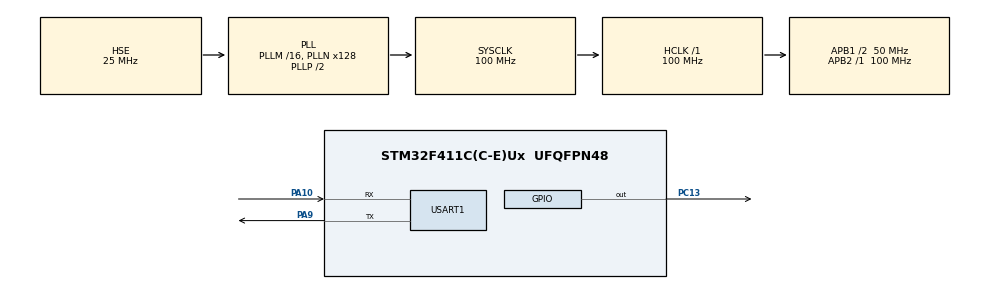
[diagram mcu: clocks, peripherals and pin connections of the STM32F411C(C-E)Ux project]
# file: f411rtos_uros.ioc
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Dma.Request0=USART1_RX
Dma.Request1=USART1_TX
Dma.USART1_RX.0.Direction=DMA_PERIPH_TO_MEMORY
Dma.USART1_RX.0.FIFOMode=DMA_FIFOMODE_DISABLE
Dma.USART1_RX.0.Instance=DMA2_Stream2
Dma.USART1_RX.0.MemDataAlignment=DMA_MDATAALIGN_BYTE
Dma.USART1_RX.0.MemInc=DMA_MINC_ENABLE
Dma.USART1_RX.0.Mode=DMA_CIRCULAR
Dma.USART1_RX.0.PeriphDataAlignment=DMA_PDATAALIGN_BYTE
Dma.USART1_RX.0.PeriphInc=DMA_PINC_DISABLE
Dma.USART1_RX.0.Priority=DMA_PRIORITY_HIGH
Dma.USART1_TX.1.Direction=DMA_MEMORY_TO_PERIPH
Dma.USART1_TX.1.FIFOMode=DMA_FIFOMODE_DISABLE
Dma.USART1_TX.1.Instance=DMA2_Stream7
Dma.USART1_TX.1.MemDataAlignment=DMA_MDATAALIGN_BYTE
Dma.USART1_TX.1.MemInc=DMA_MINC_ENABLE
Dma.USART1_TX.1.Mode=DMA_NORMAL
Dma.USART1_TX.1.PeriphDataAlignment=DMA_PDATAALIGN_BYTE
Dma.USART1_TX.1.PeriphInc=DMA_PINC_DISABLE
Dma.USART1_TX.1.Priority=DMA_PRIORITY_HIGH
FREERTOS.Tasks01=defaultTask,24,128,StartDefaultTask,Default,NULL,Dynamic,NULL,NULL;rosTask,40,3000,StartRosTask,Default,NULL,Dynamic,NULL,NULL
FREERTOS.configENABLE_FPU=1
FREERTOS.configUSE_NEWLIB_REENTRANT=1
Mcu.Family=STM32F4
Mcu.Name=STM32F411C(C-E)Ux
Mcu.Package=UFQFPN48
NVIC.DMA2_Stream2_IRQn=true\:5\:0\:false\:false\:true\:true\:false\:true\:true
NVIC.DMA2_Stream7_IRQn=true\:5\:0\:false\:false\:true\:true\:false\:true\:true
NVIC.PriorityGroup=NVIC_PRIORITYGROUP_4
NVIC.TIM1_UP_TIM10_IRQn=true\:15\:0\:false\:false\:true\:false\:false\:true\:true
NVIC.TimeBase=TIM1_UP_TIM10_IRQn
NVIC.TimeBaseIP=TIM1
NVIC.USART1_IRQn=true\:5\:0\:false\:false\:true\:true\:true\:true\:true
PA10.Mode=Asynchronous
PA10.Signal=USART1_RX
PA13.Mode=Serial_Wire
PA13.Signal=SYS_JTMS-SWDIO
PA14.Mode=Serial_Wire
PA14.Signal=SYS_JTCK-SWCLK
PA9.Mode=Asynchronous
PA9.Signal=USART1_TX
PC13-ANTI_TAMP.Signal=GPIO_Output
PH0\ -\ OSC_IN.Mode=HSE-External-Oscillator
PH0\ -\ OSC_IN.Signal=RCC_OSC_IN
PH1\ -\ OSC_OUT.Mode=HSE-External-Oscillator
PH1\ -\ OSC_OUT.Signal=RCC_OSC_OUT
ProjectManager.HeapSize=0x200
ProjectManager.StackSize=0x400
ProjectManager.TargetToolchain=STM32CubeIDE
RCC.48MHZClocksFreq_Value=50000000
RCC.AHBFreq_Value=100000000
RCC.APB1CLKDivider=RCC_HCLK_DIV2
RCC.APB1Freq_Value=50000000
RCC.APB1TimFreq_Value=100000000
RCC.APB2Freq_Value=100000000
RCC.APB2TimFreq_Value=100000000
RCC.CortexFreq_Value=100000000
RCC.HCLKFreq_Value=100000000
RCC.HSE_VALUE=25000000
RCC.HSI_VALUE=16000000
RCC.LSE_VALUE=32768
RCC.PLLN=128
RCC.PLLSourceVirtual=RCC_PLLSOURCE_HSE
RCC.SYSCLKFreq_VALUE=100000000
RCC.SYSCLKSource=RCC_SYSCLKSOURCE_PLLCLK
RCC.VCOOutputFreq_Value=200000000
USART1.VirtualMode=VM_ASYNC
VP_FREERTOS_VS_CMSIS_V2.Mode=CMSIS_V2
VP_SYS_VS_tim1.Mode=TIM1
board=custom

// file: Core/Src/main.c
/* USER CODE BEGIN Header */
/**
  ******************************************************************************
  * @file           : main.c
  * @brief          : Main program body
  ******************************************************************************
  * @attention
  *
  * Copyright (c) 2025 STMicroelectronics.
  * All rights reserved.
  *
  * This software is licensed under terms that can be found in the LICENSE file
  * in the root directory of this software component.
  * If no LICENSE file comes with this software, it is provided AS-IS.
  *
  ******************************************************************************
  */
/* USER CODE END Header */
#include "main.h"
#include "cmsis_os.h"

/* USER CODE BEGIN Includes */

// micro-ros includes
#include <rcl/rcl.h>
#include <rcl/error_handling.h>
#include <rclc/rclc.h>
#include <rclc/executor.h>
#include <uxr/client/transport.h>
#include <rmw_microxrcedds_c/config.h>
#include <rmw_microros/rmw_microros.h>

#include <std_msgs/msg/int32.h>
#include <geometry_msgs/msg/twist.h>

/* USER CODE END Includes */

UART_HandleTypeDef huart1;
DMA_HandleTypeDef hdma_usart1_rx;
DMA_HandleTypeDef hdma_usart1_tx;

/* Definitions for defaultTask */
osThreadId_t defaultTaskHandle;
const osThreadAttr_t defaultTask_attributes = {
  .name = "defaultTask",
  .stack_size = 128 * 4,
  .priority = (osPriority_t) osPriorityNormal,
};
/* Definitions for rosTask */
osThreadId_t rosTaskHandle;
const osThreadAttr_t rosTask_attributes = {
  .name = "rosTask",
  .stack_size = 3000 * 4,
  .priority = (osPriority_t) osPriorityHigh,
};
/* USER CODE BEGIN PV */

// micro-ros node
rcl_node_t node;

// micro-ros publisher
rcl_publisher_t publisher;

// micro-ros subscriber
rcl_subscription_t cmd_vel_sub;
rclc_executor_t executor;
geometry_msgs__msg__Twist cmd_vel_msg;

volatile float v_linear = 0.0f;
volatile float v_angular = 0.0f;

//volatile uint32_t cb_count = 0;

/* USER CODE END PV */

void SystemClock_Config(void);
static void MX_GPIO_Init(void);
static void MX_DMA_Init(void);
static void MX_USART1_UART_Init(void);
void StartDefaultTask(void *argument);
void StartRosTask(void *argument);

/* USER CODE BEGIN PFP */

// micro-ros
bool cubemx_transport_open(struct uxrCustomTransport * transport);
bool cubemx_transport_close(struct uxrCustomTransport * transport);
size_t cubemx_transport_write(struct uxrCustomTransport* transport, const uint8_t * buf, size_t len, uint8_t * err);
size_t cubemx_transport_read(struct uxrCustomTransport* transport, uint8_t* buf, size_t len, int timeout, uint8_t* err);

void * microros_allocate(size_t size, void * state);
void microros_deallocate(void * pointer, void * state);
void * microros_reallocate(void * pointer, size_t size, void * state);
void * microros_zero_allocate(size_t number_of_elements, size_t size_of_element, void * state);

// micro-ros subscriber
void cmd_vel_callback(const void * msgin);

/* USER CODE END PFP */

/* USER CODE BEGIN 0 */

__attribute__((noinline)) void cmd_vel_callback(const void * msgin)
{
  const geometry_msgs__msg__Twist * msg = (const geometry_msgs__msg__Twist *)msgin;

  HAL_GPIO_TogglePin(GPIOC, GPIO_PIN_13);

  //cb_count++;

  v_linear  = msg->linear.x;
  v_angular = msg->angular.z;
}

/* USER CODE END 0 */

int main(void)
{

  /* MCU Configuration--------------------------------------------------------*/

  /* Reset of all peripherals, Initializes the Flash interface and the Systick. */
  HAL_Init();

  /* Configure the system clock */
  SystemClock_Config();

  /* Initialize all configured peripherals */
  MX_GPIO_Init();
  MX_DMA_Init();
  MX_USART1_UART_Init();

  /* Init scheduler */
  osKernelInitialize();

  /* Create the thread(s) */
  /* creation of defaultTask */
  defaultTaskHandle = osThreadNew(StartDefaultTask, NULL, &defaultTask_attributes);

  /* creation of rosTask */
  rosTaskHandle = osThreadNew(StartRosTask, NULL, &rosTask_attributes);

  /* Start scheduler */
  osKernelStart();

  /* We should never get here as control is now taken by the scheduler */

  /* Infinite loop */
  while (1)
  {

  }
}

void SystemClock_Config(void)
{
  RCC_OscInitTypeDef RCC_OscInitStruct = {0};
  RCC_ClkInitTypeDef RCC_ClkInitStruct = {0};

  /** Configure the main internal regulator output voltage
  */
  __HAL_RCC_PWR_CLK_ENABLE();
  __HAL_PWR_VOLTAGESCALING_CONFIG(PWR_REGULATOR_VOLTAGE_SCALE1);

  /** Initializes the RCC Oscillators according to the specified parameters
  * in the RCC_OscInitTypeDef structure.
  */
  RCC_OscInitStruct.OscillatorType = RCC_OSCILLATORTYPE_HSE;
  RCC_OscInitStruct.HSEState = RCC_HSE_ON;
  RCC_OscInitStruct.PLL.PLLState = RCC_PLL_ON;
  RCC_OscInitStruct.PLL.PLLSource = RCC_PLLSOURCE_HSE;
  RCC_OscInitStruct.PLL.PLLM = 16;
  RCC_OscInitStruct.PLL.PLLN = 128;
  RCC_OscInitStruct.PLL.PLLP = RCC_PLLP_DIV2;
  RCC_OscInitStruct.PLL.PLLQ = 4;
  if (HAL_RCC_OscConfig(&RCC_OscInitStruct) != HAL_OK)
  {
    Error_Handler();
  }

  /** Initializes the CPU, AHB and APB buses clocks
  */
  RCC_ClkInitStruct.ClockType = RCC_CLOCKTYPE_HCLK|RCC_CLOCKTYPE_SYSCLK
                              |RCC_CLOCKTYPE_PCLK1|RCC_CLOCKTYPE_PCLK2;
  RCC_ClkInitStruct.SYSCLKSource = RCC_SYSCLKSOURCE_PLLCLK;
  RCC_ClkInitStruct.AHBCLKDivider = RCC_SYSCLK_DIV1;
  RCC_ClkInitStruct.APB1CLKDivider = RCC_HCLK_DIV2;
  RCC_ClkInitStruct.APB2CLKDivider = RCC_HCLK_DIV1;

  if (HAL_RCC_ClockConfig(&RCC_ClkInitStruct, FLASH_LATENCY_3) != HAL_OK)
  {
    Error_Handler();
  }
}

static void MX_USART1_UART_Init(void)
{

  huart1.Instance = USART1;
  huart1.Init.BaudRate = 115200;
  huart1.Init.WordLength = UART_WORDLENGTH_8B;
  huart1.Init.StopBits = UART_STOPBITS_1;
  huart1.Init.Parity = UART_PARITY_NONE;
  huart1.Init.Mode = UART_MODE_TX_RX;
  huart1.Init.HwFlowCtl = UART_HWCONTROL_NONE;
  huart1.Init.OverSampling = UART_OVERSAMPLING_16;
  if (HAL_UART_Init(&huart1) != HAL_OK)
  {
    Error_Handler();
  }

}

static void MX_DMA_Init(void)
{

  /* DMA controller clock enable */
  __HAL_RCC_DMA2_CLK_ENABLE();

  /* DMA interrupt init */
  /* DMA2_Stream2_IRQn interrupt configuration */
  HAL_NVIC_SetPriority(DMA2_Stream2_IRQn, 5, 0);
  HAL_NVIC_EnableIRQ(DMA2_Stream2_IRQn);
  /* DMA2_Stream7_IRQn interrupt configuration */
  HAL_NVIC_SetPriority(DMA2_Stream7_IRQn, 5, 0);
  HAL_NVIC_EnableIRQ(DMA2_Stream7_IRQn);

}

static void MX_GPIO_Init(void)
{
  GPIO_InitTypeDef GPIO_InitStruct = {0};

  /* GPIO Ports Clock Enable */
  __HAL_RCC_GPIOC_CLK_ENABLE();
  __HAL_RCC_GPIOH_CLK_ENABLE();
  __HAL_RCC_GPIOA_CLK_ENABLE();

  /*Configure GPIO pin Output Level */
  HAL_GPIO_WritePin(GPIOC, GPIO_PIN_13, GPIO_PIN_RESET);

  /*Configure GPIO pin : PC13 */
  GPIO_InitStruct.Pin = GPIO_PIN_13;
  GPIO_InitStruct.Mode = GPIO_MODE_OUTPUT_PP;
  GPIO_InitStruct.Pull = GPIO_NOPULL;
  GPIO_InitStruct.Speed = GPIO_SPEED_FREQ_LOW;
  HAL_GPIO_Init(GPIOC, &GPIO_InitStruct);

}

void StartDefaultTask(void *argument)
{
  /* USER CODE BEGIN 5 */
  /* Infinite loop */
  for(;;)
  {
	// my led blink
	//HAL_GPIO_TogglePin(GPIOC, GPIO_PIN_13);
	osDelay(1000);
  }
  /* USER CODE END 5 */
}

void StartRosTask(void *argument)
{
  /* USER CODE BEGIN StartRosTask */
	  std_msgs__msg__Int32 msg;
	  rclc_support_t support;
	  rcl_allocator_t allocator;

	  /*
	  static bool initialized = false;
	  if (initialized) vTaskDelete(NULL);
	  initialized = true;
	  */
	  osDelay(1000);

	  rmw_uros_set_custom_transport(
	    true,
	    (void *) &huart1,
	    cubemx_transport_open,
	    cubemx_transport_close,
	    cubemx_transport_write,
	    cubemx_transport_read);

	  /*
	  while (rmw_uros_ping_agent(1000, 1) != RMW_RET_OK)
	  {
	    osDelay(1000);
	  }
	  */

	  //rmw_uros_sync_session(1000);

	  /*
	  rcl_allocator_t freeRTOS_allocator = rcutils_get_zero_initialized_allocator();
	  freeRTOS_allocator.allocate = microros_allocate;
	  freeRTOS_allocator.deallocate = microros_deallocate;
	  freeRTOS_allocator.reallocate = microros_reallocate;
	  freeRTOS_allocator.zero_allocate =  microros_zero_allocate;

	  if (!rcutils_set_default_allocator(&freeRTOS_allocator)) {
	      printf("Error on default allocators (line %d)\n", __LINE__);
	  }
	  */

	  // micro-ROS app

	  allocator = rcl_get_default_allocator();

	  // create init_options
	  rclc_support_init(&support, 0, NULL, &allocator);

	  // create node
	  rclc_node_init_default(&node, "stm32_node", "", &support);

	  // create publisher
	  rclc_publisher_init_default(
	    &publisher,
	    &node,
	    ROSIDL_GET_MSG_TYPE_SUPPORT(std_msgs, msg, Int32),
	    "cubemx_publisher");

	  msg.data = 0;

	  // create subscriber
	  geometry_msgs__msg__Twist__init(&cmd_vel_msg);

	  rclc_subscription_init_default(
	    &cmd_vel_sub,
	    &node,
	    ROSIDL_GET_MSG_TYPE_SUPPORT(geometry_msgs, msg, Twist),
	    "/cmd_vel"
	  );

	  // micro-ros subscriber executor
	  rclc_executor_init(&executor, &support.context, 1, &allocator);

	  rclc_executor_add_subscription(
	    &executor,
	    &cmd_vel_sub,
	    &cmd_vel_msg,
	    &cmd_vel_callback,
	    ON_NEW_DATA
	  );

	  for (;;)
	  {
	  // publisher
	  if ((msg.data % 1000) == 0) {
		  rcl_ret_t ret = rcl_publish(&publisher, &msg, NULL);
		  if (ret != RCL_RET_OK)
		  {
			printf("Error publishing (line %d)\n", __LINE__);
		  }
	    }
		msg.data++;

	    // spin (subscribers run on spin?)
		rclc_executor_spin_some(&executor, RCL_MS_TO_NS(5));
	    osDelay(1);
	  }

  /* USER CODE END StartRosTask */
}

void HAL_TIM_PeriodElapsedCallback(TIM_HandleTypeDef *htim)
{
  if (htim->Instance == TIM1)
  {
    HAL_IncTick();
  }
}

void Error_Handler(void)
{
  __disable_irq();
  while (1)
  {
  }
}
